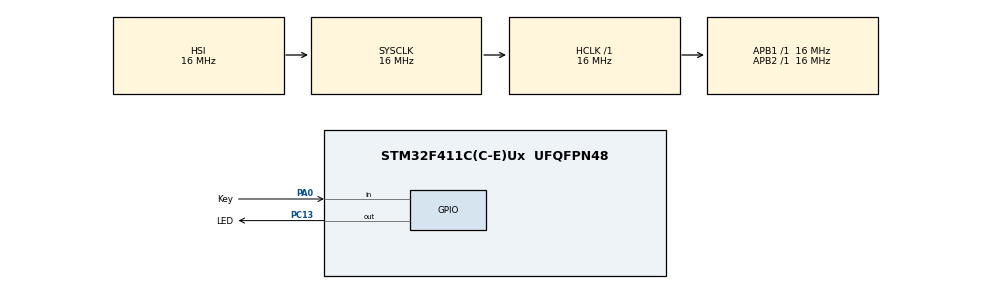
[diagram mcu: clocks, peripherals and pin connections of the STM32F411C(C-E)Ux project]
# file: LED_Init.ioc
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Mcu.Family=STM32F4
Mcu.Name=STM32F411C(C-E)Ux
Mcu.Package=UFQFPN48
NVIC.PriorityGroup=NVIC_PRIORITYGROUP_4
PA0-WKUP.GPIO_Label=Key
PA0-WKUP.GPIO_PuPd=GPIO_PULLUP
PA0-WKUP.Signal=GPIO_Input
PA13.Mode=Serial_Wire
PA13.Signal=SYS_JTMS-SWDIO
PA14.Mode=Serial_Wire
PA14.Signal=SYS_JTCK-SWCLK
PC13-ANTI_TAMP.GPIO_Label=LED
PC13-ANTI_TAMP.Signal=GPIO_Output
PC14-OSC32_IN.Mode=LSE-External-Oscillator
PC14-OSC32_IN.Signal=RCC_OSC32_IN
PC15-OSC32_OUT.Mode=LSE-External-Oscillator
PC15-OSC32_OUT.Signal=RCC_OSC32_OUT
PH0\ -\ OSC_IN.Mode=HSE-External-Oscillator
PH0\ -\ OSC_IN.Signal=RCC_OSC_IN
PH1\ -\ OSC_OUT.Mode=HSE-External-Oscillator
PH1\ -\ OSC_OUT.Signal=RCC_OSC_OUT
ProjectManager.HeapSize=0x200
ProjectManager.StackSize=0x400
ProjectManager.TargetToolchain=MDK-ARM V5.32
RCC.AHBFreq_Value=16000000
RCC.APB1Freq_Value=16000000
RCC.APB2Freq_Value=16000000
RCC.CortexFreq_Value=16000000
RCC.HSE_VALUE=25000000
RCC.HSI_VALUE=16000000
RCC.SYSCLKFreq_VALUE=16000000
RCC.VCOOutputFreq_Value=192000000
board=custom

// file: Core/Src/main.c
/* USER CODE BEGIN Header */
/**
  ******************************************************************************
  * @file           : main.c
  * @brief          : Main program body
  ******************************************************************************
  * @attention
  *
  * Copyright (c) 2026 STMicroelectronics.
  * All rights reserved.
  *
  * This software is licensed under terms that can be found in the LICENSE file
  * in the root directory of this software component.
  * If no LICENSE file comes with this software, it is provided AS-IS.
  *
  ******************************************************************************
  */
/* USER CODE END Header */
#include "main.h"
#include "gpio.h"

/* USER CODE BEGIN PV */
uint8_t last_state = 1;
uint8_t status = 0;
uint8_t key_state = 1;        // 当前 Key 稳定状态
uint8_t last_key_state = 1;   // 上一次读取的 Key 电平
/* USER CODE END PV */

void SystemClock_Config(void);

/* USER CODE BEGIN 0 */
void Key_Scan(void)
{
    uint8_t current_key_state = HAL_GPIO_ReadPin(Key_GPIO_Port, Key_Pin);  // 读取当前按键电平

    // 检测按键是否被按下（边沿检测：当前低电平且上一次高电平）
    if (current_key_state == GPIO_PIN_RESET && last_key_state == GPIO_PIN_SET)
    {
        // 简单的软件消抖（延时 10ms 再次检测）
        HAL_Delay(10);
        if (HAL_GPIO_ReadPin(Key_GPIO_Port, Key_Pin) == GPIO_PIN_RESET)
        {
            // 按键有效按下，翻转 status
            status = !status;  // status 取反
        }
    }

    last_key_state = current_key_state;  // 更新上一次状态
}
/* USER CODE END 0 */

int main(void)
{

  /* MCU Configuration--------------------------------------------------------*/

  /* Reset of all peripherals, Initializes the Flash interface and the Systick. */
  HAL_Init();

  /* Configure the system clock */
  SystemClock_Config();

  /* Initialize all configured peripherals */
  MX_GPIO_Init();

  /* Infinite loop */
  while (1)
  {
		Key_Scan();  // 轮询检测按键

		if (status == 1)
		{
				// 按键按下后的操作
				HAL_GPIO_TogglePin(LED_GPIO_Port, LED_Pin);
				HAL_Delay(100);
		}
		else if (status == 0 && last_state != 0)		// 只有当 status 从 1 变为 0 时才关灯
		{
				// 再次按下后的操作
				HAL_GPIO_WritePin(LED_GPIO_Port, LED_Pin, GPIO_PIN_SET);
		}
		last_state = status;
  }
}

void SystemClock_Config(void)
{
  RCC_OscInitTypeDef RCC_OscInitStruct = {0};
  RCC_ClkInitTypeDef RCC_ClkInitStruct = {0};

  /** Configure the main internal regulator output voltage
  */
  __HAL_RCC_PWR_CLK_ENABLE();
  __HAL_PWR_VOLTAGESCALING_CONFIG(PWR_REGULATOR_VOLTAGE_SCALE1);

  /** Initializes the RCC Oscillators according to the specified parameters
  * in the RCC_OscInitTypeDef structure.
  */
  RCC_OscInitStruct.OscillatorType = RCC_OSCILLATORTYPE_HSI;
  RCC_OscInitStruct.HSIState = RCC_HSI_ON;
  RCC_OscInitStruct.HSICalibrationValue = RCC_HSICALIBRATION_DEFAULT;
  RCC_OscInitStruct.PLL.PLLState = RCC_PLL_NONE;
  if (HAL_RCC_OscConfig(&RCC_OscInitStruct) != HAL_OK)
  {
    Error_Handler();
  }

  /** Initializes the CPU, AHB and APB buses clocks
  */
  RCC_ClkInitStruct.ClockType = RCC_CLOCKTYPE_HCLK|RCC_CLOCKTYPE_SYSCLK
                              |RCC_CLOCKTYPE_PCLK1|RCC_CLOCKTYPE_PCLK2;
  RCC_ClkInitStruct.SYSCLKSource = RCC_SYSCLKSOURCE_HSI;
  RCC_ClkInitStruct.AHBCLKDivider = RCC_SYSCLK_DIV1;
  RCC_ClkInitStruct.APB1CLKDivider = RCC_HCLK_DIV1;
  RCC_ClkInitStruct.APB2CLKDivider = RCC_HCLK_DIV1;

  if (HAL_RCC_ClockConfig(&RCC_ClkInitStruct, FLASH_LATENCY_0) != HAL_OK)
  {
    Error_Handler();
  }
}

void Error_Handler(void)
{
  __disable_irq();
  while (1)
  {
  }
}
